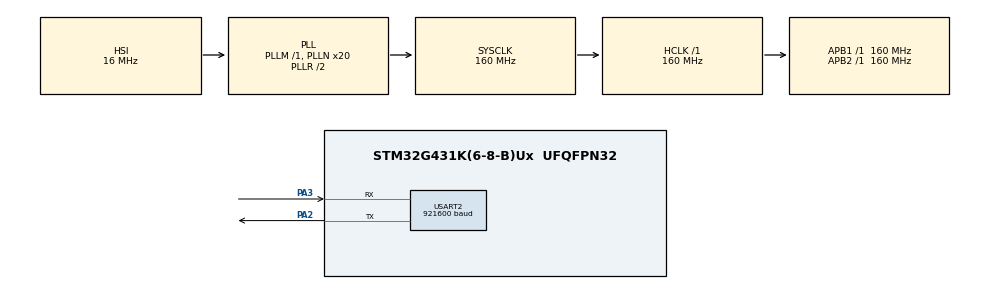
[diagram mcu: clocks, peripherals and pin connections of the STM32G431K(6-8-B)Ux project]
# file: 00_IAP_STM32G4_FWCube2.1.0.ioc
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Mcu.Family=STM32G4
Mcu.Name=STM32G431K(6-8-B)Ux
Mcu.Package=UFQFPN32
NVIC.PriorityGroup=NVIC_PRIORITYGROUP_4
NVIC.USART2_IRQn=true\:0\:0\:false\:false\:true\:true\:true\:true
PA13.Mode=Serial_Wire
PA13.Signal=SYS_JTMS-SWDIO
PA14.Mode=Serial_Wire
PA14.Signal=SYS_JTCK-SWCLK
PA2.Mode=Asynchronous
PA2.Signal=USART2_TX
PA3.Mode=Asynchronous
PA3.Signal=USART2_RX
PB3.Signal=SYS_JTDO-SWO
ProjectManager.HeapSize=0x200
ProjectManager.StackSize=0x400
ProjectManager.TargetToolchain=STM32CubeIDE
RCC.ADC12Freq_Value=160000000
RCC.AHBFreq_Value=160000000
RCC.APB1Freq_Value=160000000
RCC.APB1TimFreq_Value=160000000
RCC.APB2Freq_Value=160000000
RCC.APB2TimFreq_Value=160000000
RCC.CortexFreq_Value=160000000
RCC.EXTERNAL_CLOCK_VALUE=12288000
RCC.HCLKFreq_Value=160000000
RCC.HSE_VALUE=8000000
RCC.HSI48_VALUE=48000000
RCC.HSI_VALUE=16000000
RCC.LSE_VALUE=32768
RCC.PLLN=20
RCC.SYSCLKFreq_VALUE=160000000
RCC.SYSCLKSource=RCC_SYSCLKSOURCE_PLLCLK
RCC.USBFreq_Value=160000000
RCC.VCOOutputFreq_Value=320000000
USART2.BaudRate=921600
USART2.VirtualMode-Asynchronous=VM_ASYNC
VP_SYS_VS_DBSignals.Mode=DisableDeadBatterySignals
board=custom

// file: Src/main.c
/* USER CODE BEGIN Header */
/**
  ******************************************************************************
  * @file           : main.c
  * @brief          : Main program body
  ******************************************************************************
  * @attention
  *
  * Copyright (c) 2026 STMicroelectronics.
  * All rights reserved.
  *
  * This software is licensed under terms that can be found in the LICENSE file
  * in the root directory of this software component.
  * If no LICENSE file comes with this software, it is provided AS-IS.
  *
  ******************************************************************************
  */
/* USER CODE END Header */
#include "main.h"

/* USER CODE BEGIN Includes */
#include "common.h"
#include "flash_if.h"
#include "menu.h"
/* USER CODE END Includes */

UART_HandleTypeDef huart2;

/* USER CODE BEGIN PV */
uint32_t tick_cnt = 0;
uint32_t cnt_ms   = 0;
uint8_t  IAP_mode = 0;

extern pFunction JumpToApplication;
extern uint32_t  JumpAddress;
/* USER CODE END PV */

void SystemClock_Config(void);
static void MX_GPIO_Init(void);
static void MX_USART2_UART_Init(void);

int main(void)
{

  /* USER CODE BEGIN 1 */
  uint8_t bytes_read = 0;
  /* USER CODE END 1 */

  /* MCU Configuration--------------------------------------------------------*/

  /* Reset of all peripherals, Initializes the Flash interface and the Systick. */
  HAL_Init();

  /* Configure the system clock */
  SystemClock_Config();

  /* Initialize all configured peripherals */
  MX_GPIO_Init();
  MX_USART2_UART_Init();
  /* USER CODE BEGIN 2 */
  IAP_mode = 0;
  FLASH_If_Init();

  Main_Menu();
  IAP_mode = 0;

  uint32_t msp_val = *(__IO uint32_t *)USER_START_ADDRESS;
  if ((msp_val != 0xFFFFFFFFu) &&
      (msp_val >= 0x20000000u) &&
      (msp_val <= 0x20008000u))
  {
    Serial_PutString((uint8_t *)"\r\nStart application...\r\n");
    HAL_Delay(200);
    HAL_RCC_DeInit();
    HAL_DeInit();
    SysTick->CTRL = 0;
    SysTick->LOAD = 0;
    SysTick->VAL  = 0;
    JumpAddress = *(__IO uint32_t *)(USER_START_ADDRESS + 4u);
    JumpToApplication = (pFunction)JumpAddress;
    __set_MSP(*(__IO uint32_t *)USER_START_ADDRESS);
    JumpToApplication();
  }

  Serial_PutString((uint8_t *)"\r\n[IAP] No valid application found.\r\n");
  Serial_PutString((uint8_t *)"[IAP] Press ESC x3 to download firmware, or 'rrr' to reset.\r\n");

  /* USER CODE END 2 */

  /* Infinite loop */
  while (1)
  {

    /* USER CODE BEGIN 3 */
    uint8_t key2 = 0;
    if (HAL_UART_Receive(&UartHandle, &key2, 1, 2) != HAL_OK)
    {
      continue;
    }

    if (key2 == 0x1Bu)
    {
      bytes_read++;
      if (bytes_read == 3u)
      {
        bytes_read = 0;
        Serial_PutString((uint8_t *)"\r\n");
        COM_StatusTypeDef dl = SerialDownload();
        if (dl == COM_OK)
        {
          Serial_PutString((uint8_t *)"\r\nDownloaded. Starting application...\r\n");
          HAL_Delay(500);
          HAL_RCC_DeInit();
          HAL_DeInit();
          SysTick->CTRL = 0;
          SysTick->LOAD = 0;
          SysTick->VAL  = 0;
          JumpAddress = *(__IO uint32_t *)(USER_START_ADDRESS + 4u);
          JumpToApplication = (pFunction)JumpAddress;
          __set_MSP(*(__IO uint32_t *)USER_START_ADDRESS);
          JumpToApplication();
        }
        else
        {
          Serial_PutString((uint8_t *)"[IAP] Download failed. Press ESC x3 again or 'rrr' to reset.\r\n");
        }
      }
    }
    else if ((key2 == 'r') || (key2 == 'R'))
    {
      bytes_read++;
      if (bytes_read == 3u)
      {
        Serial_PutString((uint8_t *)"\r\nRestart...\r\n");
        HAL_Delay(100);
        __NVIC_SystemReset();
      }
    }
    else
    {
      bytes_read = 0;
    }
  }
  /* USER CODE END 3 */
}

void SystemClock_Config(void)
{
  RCC_OscInitTypeDef RCC_OscInitStruct = {0};
  RCC_ClkInitTypeDef RCC_ClkInitStruct = {0};

  /** Configure the main internal regulator output voltage
  */
  HAL_PWREx_ControlVoltageScaling(PWR_REGULATOR_VOLTAGE_SCALE1_BOOST);

  /** Initializes the RCC Oscillators according to the specified parameters
  * in the RCC_OscInitTypeDef structure.
  */
  RCC_OscInitStruct.OscillatorType = RCC_OSCILLATORTYPE_HSI;
  RCC_OscInitStruct.HSIState = RCC_HSI_ON;
  RCC_OscInitStruct.HSICalibrationValue = RCC_HSICALIBRATION_DEFAULT;
  RCC_OscInitStruct.PLL.PLLState = RCC_PLL_ON;
  RCC_OscInitStruct.PLL.PLLSource = RCC_PLLSOURCE_HSI;
  RCC_OscInitStruct.PLL.PLLM = RCC_PLLM_DIV1;
  RCC_OscInitStruct.PLL.PLLN = 20;
  RCC_OscInitStruct.PLL.PLLP = RCC_PLLP_DIV2;
  RCC_OscInitStruct.PLL.PLLQ = RCC_PLLQ_DIV2;
  RCC_OscInitStruct.PLL.PLLR = RCC_PLLR_DIV2;
  if (HAL_RCC_OscConfig(&RCC_OscInitStruct) != HAL_OK)
  {
    Error_Handler();
  }

  /** Initializes the CPU, AHB and APB buses clocks
  */
  RCC_ClkInitStruct.ClockType = RCC_CLOCKTYPE_HCLK|RCC_CLOCKTYPE_SYSCLK
                              |RCC_CLOCKTYPE_PCLK1|RCC_CLOCKTYPE_PCLK2;
  RCC_ClkInitStruct.SYSCLKSource = RCC_SYSCLKSOURCE_PLLCLK;
  RCC_ClkInitStruct.AHBCLKDivider = RCC_SYSCLK_DIV1;
  RCC_ClkInitStruct.APB1CLKDivider = RCC_HCLK_DIV1;
  RCC_ClkInitStruct.APB2CLKDivider = RCC_HCLK_DIV1;

  if (HAL_RCC_ClockConfig(&RCC_ClkInitStruct, FLASH_LATENCY_4) != HAL_OK)
  {
    Error_Handler();
  }
}

static void MX_USART2_UART_Init(void)
{

  huart2.Instance = USART2;
  huart2.Init.BaudRate = 921600;
  huart2.Init.WordLength = UART_WORDLENGTH_8B;
  huart2.Init.StopBits = UART_STOPBITS_1;
  huart2.Init.Parity = UART_PARITY_NONE;
  huart2.Init.Mode = UART_MODE_TX_RX;
  huart2.Init.HwFlowCtl = UART_HWCONTROL_NONE;
  huart2.Init.OverSampling = UART_OVERSAMPLING_16;
  huart2.Init.OneBitSampling = UART_ONE_BIT_SAMPLE_DISABLE;
  huart2.Init.ClockPrescaler = UART_PRESCALER_DIV1;
  huart2.AdvancedInit.AdvFeatureInit = UART_ADVFEATURE_NO_INIT;
  if (HAL_UART_Init(&huart2) != HAL_OK)
  {
    Error_Handler();
  }
  if (HAL_UARTEx_SetTxFifoThreshold(&huart2, UART_TXFIFO_THRESHOLD_1_8) != HAL_OK)
  {
    Error_Handler();
  }
  if (HAL_UARTEx_SetRxFifoThreshold(&huart2, UART_RXFIFO_THRESHOLD_1_8) != HAL_OK)
  {
    Error_Handler();
  }
  if (HAL_UARTEx_DisableFifoMode(&huart2) != HAL_OK)
  {
    Error_Handler();
  }

}

static void MX_GPIO_Init(void)
{

  /* GPIO Ports Clock Enable */
  __HAL_RCC_GPIOA_CLK_ENABLE();
  __HAL_RCC_GPIOB_CLK_ENABLE();

}

void Error_Handler(void)
{
  __disable_irq();
  while (1)
  {
  }
}
